AUTOSAR XML (schema 4-0-3)
package /ComponentTypes
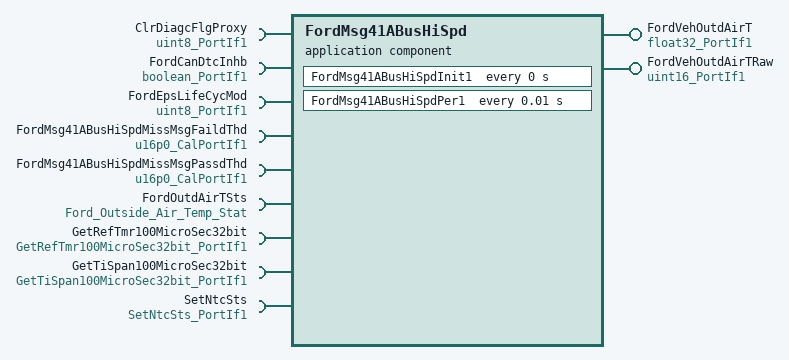
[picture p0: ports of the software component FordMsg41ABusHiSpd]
  application sw component type FordMsg41ABusHiSpd
    provide port FordVehOutdAirT: nonqueued-sender-com-spec{data-element=Val, init-value=86.5}, provided-interface=float32_PortIf1
    provide port FordVehOutdAirTRaw: nonqueued-sender-com-spec{data-element=Val, init-value=254}, provided-interface=uint16_PortIf1
    9 x require port:
      ClrDiagcFlgProxy: nonqueued-receiver-com-spec{data-element=Val, filter=data-filter-type=ALWAYS, init-value=0}, required-interface=uint8_PortIf1
      FordCanDtcInhb: nonqueued-receiver-com-spec{data-element=Logl, filter=data-filter-type=ALWAYS, init-value=1}, required-interface=boolean_PortIf1
      FordEpsLifeCycMod: nonqueued-receiver-com-spec{data-element=Val, filter=data-filter-type=ALWAYS, init-value=0}, required-interface=uint8_PortIf1
      FordMsg41ABusHiSpdMissMsgFaildThd: parameter-require-com-spec{init-value=5000, parameter=Val}, required-interface=u16p0_CalPortIf1
      FordMsg41ABusHiSpdMissMsgPassdThd: parameter-require-com-spec{init-value=0, parameter=Val}, required-interface=u16p0_CalPortIf1
      FordOutdAirTSts: nonqueued-receiver-com-spec{data-element=Ford_Outside_Air_Temp_Stat, filter=data-filter-type=ALWAYS, init-value=254}, required-interface=Ford_Outside_Air_Temp_Stat
      GetRefTmr100MicroSec32bit: client-com-spec=Oper, required-interface=GetRefTmr100MicroSec32bit_PortIf1
      GetTiSpan100MicroSec32bit: client-com-spec=Oper, required-interface=GetTiSpan100MicroSec32bit_PortIf1
      SetNtcSts: client-com-spec=Oper, required-interface=SetNtcSts_PortIf1
    behavior FordMsg41ABusHiSpd_InternalBehavior
      ar-typed-per-instance-memorys:
        6 x data, all with sw-calibration-access=READ-ONLY:
          ClrDiagcFlgProxyPrev: type=uint8
          FordVehMsg41AMiss: type=boolean
          FordVehOutdAirTPrev: type=float32
          FordVehOutdAirTRawPrev: type=uint16
          MissMsgFaildRefTi: type=uint32
          MissMsgPassdRefTi: type=uint32
      timing event FordMsg41ABusHiSpd_InitEvent: start-on-event=FordMsg41ABusHiSpdInit1, period=0
      timing event TMT_FordMsg41ABusHiSpdPer1: start-on-event=FordMsg41ABusHiSpdPer1, period=0.01
      port-api-options:
        enable-take-address=false, indirect-api=false, port=ClrDiagcFlgProxy
        enable-take-address=false, indirect-api=false, port=FordCanDtcInhb
        enable-take-address=false, indirect-api=false, port=FordEpsLifeCycMod
        enable-take-address=false, indirect-api=false, port=FordMsg41ABusHiSpdMissMsgFaildThd
        enable-take-address=false, indirect-api=false, port=FordMsg41ABusHiSpdMissMsgPassdThd
        enable-take-address=false, indirect-api=false, port=FordOutdAirTSts
        enable-take-address=false, indirect-api=false, port=FordVehOutdAirT
        enable-take-address=false, indirect-api=false, port=FordVehOutdAirTRaw
        enable-take-address=false, indirect-api=false, port=GetRefTmr100MicroSec32bit
        enable-take-address=false, indirect-api=false, port=GetTiSpan100MicroSec32bit
        enable-take-address=false, indirect-api=false, port=SetNtcSts
      runnable FordMsg41ABusHiSpdInit1
        sync call SC_GetRefTmr100MicroSec32bit_Oper: operation=GetRefTmr100MicroSec32bit.Oper, timeout=0
      runnable FordMsg41ABusHiSpdPer1
        data-receive-point-by-arguments:
          4 x access:
            REC_ClrDiagcFlgProxy_Val: accessed-variable=ClrDiagcFlgProxy.Val
            REC_FordCanDtcInhb_Logl: accessed-variable=FordCanDtcInhb.Logl
            REC_FordEpsLifeCycMod_Val: accessed-variable=FordEpsLifeCycMod.Val
            REC_FordOutdAirTSts_Ford_Outside_Air_Temp_Stat: accessed-variable=FordOutdAirTSts.Ford_Outside_Air_Temp_Stat
        data-send-points:
          access SEND_FordVehOutdAirT_Val: accessed-variable=FordVehOutdAirT.Val
          access SEND_FordVehOutdAirTRaw_Val: accessed-variable=FordVehOutdAirTRaw.Val
        sync call SC_GetRefTmr100MicroSec32bit_Oper: operation=GetRefTmr100MicroSec32bit.Oper, timeout=0
        sync call SC_GetTiSpan100MicroSec32bit_Oper: operation=GetTiSpan100MicroSec32bit.Oper, timeout=0
        sync call SC_SetNtcSts_Oper: operation=SetNtcSts.Oper, timeout=0
  swc implementation FordMsg41ABusHiSpd_Implementation: behavior=FordMsg41ABusHiSpd_InternalBehavior
    code-descriptors:
      code Default: artifact-descriptors=autosar-engineering-object={short-label=Default, category=SWSRC}
